# CY8C4245AXI_483 register map
File version: 0.1
PSoC 4200
Registers are 32-bit, read-write, no defined reset value unless marked. A register's access mark holds for its fields unless they carry their own. Offsets are from the block's base; lines under a group give offsets from that group; [hi:lo] are bit positions; {n}, {i} and the like mark numbered series; 'fields as' and 'values as' point back to an identical list; <NAME> marks a mode.

## Memory map
0x00000000 Servo_PWM_3
0x00000000 Servo_PWM_0
0x00000000 Servo_PWM_1
0x00000000 Servo_PWM_2
0x00000000 Tuner — Serial Communication Block
0x00000000 I2C_MPU6050 — Serial Communication Block
0x00000000 CapSense_IDACMod — IDAC
0x00000000 BT — UART
0x00000000 Tip_Sense_ADC — Sequencing SAR ADC

## Servo_PWM_3
Base 0x00000000
0x400501C8 COUNTER — Current counter value
0x400501CC CC — Compare / capture value
0x400501D0 CC_BUF — Compare / capture buffer value
0x400501D4 PERIOD — Period value
0x400501D8 PERIOD_BUF — Period buffer value

## Servo_PWM_0
Base 0x00000000
0x40050108 COUNTER — Current counter value
0x4005010C CC — Compare / capture value
0x40050110 CC_BUF — Compare / capture buffer value
0x40050114 PERIOD — Period value
0x40050118 PERIOD_BUF — Period buffer value

## Servo_PWM_1
Base 0x00000000
0x40050188 COUNTER — Current counter value
0x4005018C CC — Compare / capture value
0x40050190 CC_BUF — Compare / capture buffer value
0x40050194 PERIOD — Period value
0x40050198 PERIOD_BUF — Period buffer value

## Servo_PWM_2
Base 0x00000000
0x40050148 COUNTER — Current counter value
0x4005014C CC — Compare / capture value
0x40050150 CC_BUF — Compare / capture buffer value
0x40050154 PERIOD — Period value
0x40050158 PERIOD_BUF — Period buffer value

## CapSense_IDACMod — IDAC
Base 0x00000000
0x40080004 CSD_IDAC_POLARITY
0x40080008 CSD_IDAC
0x4008FF00 CSD_TRIM1 — CSD IDAC TRIM1
0x4008FF04 CSD_TRIM2 — CSD IDAC TRIM2

## BT — UART
Base 0x00000000
0x400F0020 RX_BT_RX_ADDRESS1 8-bit — RX Address1 Register
0x400F0030 RX_BT_RX_ADDRESS2 8-bit — RX Address2 Register
0x400F0040 RX_BT_RX_DATA 8-bit — RX Data Register
0x400F0043 TX_BT_TX_DATA 8-bit — TX Data Register
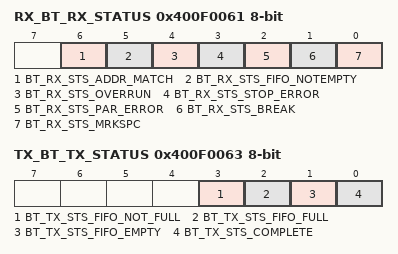
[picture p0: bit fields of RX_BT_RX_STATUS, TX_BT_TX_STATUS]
0x400F0061 RX_BT_RX_STATUS 8-bit — RX status register
  [6] BT_RX_STS_ADDR_MATCH ro, [5] BT_RX_STS_FIFO_NOTEMPTY ro, [4] BT_RX_STS_OVERRUN ro, [3] BT_RX_STS_STOP_ERROR ro, [2] BT_RX_STS_PAR_ERROR ro, [1] BT_RX_STS_BREAK ro, [0] BT_RX_STS_MRKSPC ro
0x400F0063 TX_BT_TX_STATUS 8-bit — TX status register
  [3] BT_TX_STS_FIFO_NOT_FULL ro, [2] BT_TX_STS_FIFO_FULL ro, [1] BT_TX_STS_FIFO_EMPTY ro, [0] BT_TX_STS_COMPLETE ro
